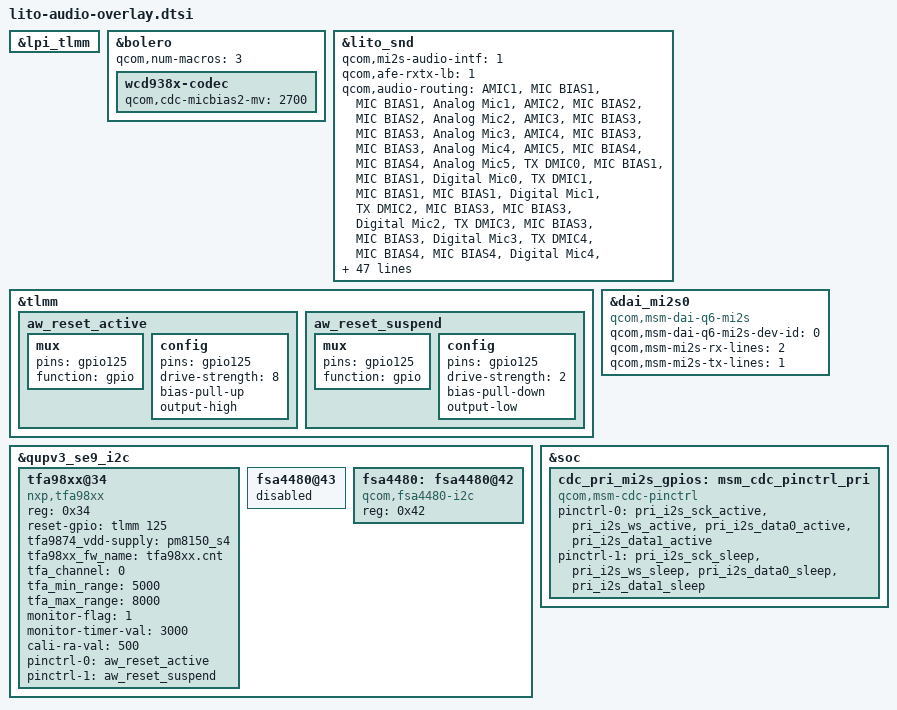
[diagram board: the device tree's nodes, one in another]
#define OPLUS_EXTERNAL_SPEAKER
#include "../../qcom/lito-audio-overlay.dtsi"
#undef OPLUS_EXTERNAL_SPEAKER

/delete-node/ &wsa_macro;
/delete-node/ &wsa_swr_gpios;
/delete-node/ &wsa_spkr_en1;
/delete-node/ &wsa_spkr_en2;
#include "oplus-audio-extend.dtsi"

&lpi_tlmm {
	/delete-node/ wsa_swr_clk_pin;
	/delete-node/ wsa_swr_data_pin;
};

&bolero {
	qcom,num-macros = <3>;
	wcd938x-codec {
		qcom,cdc-micbias2-mv = <2700>;
	};
};

&lito_snd {
	qcom,mi2s-audio-intf = <1>;
	qcom,afe-rxtx-lb = <1>;
	qcom,audio-routing =
		"AMIC1", "MIC BIAS1",
		"MIC BIAS1", "Analog Mic1",
		"AMIC2", "MIC BIAS2",
		"MIC BIAS2", "Analog Mic2",
		"AMIC3", "MIC BIAS3",
		"MIC BIAS3", "Analog Mic3",
		"AMIC4", "MIC BIAS3",
		"MIC BIAS3", "Analog Mic4",
		"AMIC5", "MIC BIAS4",
		"MIC BIAS4", "Analog Mic5",
		"TX DMIC0", "MIC BIAS1",
		"MIC BIAS1", "Digital Mic0",
		"TX DMIC1", "MIC BIAS1",
		"MIC BIAS1", "Digital Mic1",
		"TX DMIC2", "MIC BIAS3",
		"MIC BIAS3", "Digital Mic2",
		"TX DMIC3", "MIC BIAS3",
		"MIC BIAS3", "Digital Mic3",
		"TX DMIC4", "MIC BIAS4",
		"MIC BIAS4", "Digital Mic4",
		"TX DMIC5", "MIC BIAS4",
		"MIC BIAS4", "Digital Mic5",
		"IN1_HPHL", "HPHL_OUT",
		"IN2_HPHR", "HPHR_OUT",
		"IN3_AUX", "AUX_OUT",
		"TX SWR_ADC0", "ADC1_OUTPUT",
		"TX SWR_ADC1", "ADC2_OUTPUT",
		"TX SWR_ADC2", "ADC3_OUTPUT",
		"TX SWR_ADC3", "ADC4_OUTPUT",
		"TX SWR_DMIC0", "DMIC1_OUTPUT",
		"TX SWR_DMIC1", "DMIC2_OUTPUT",
		"TX SWR_DMIC2", "DMIC3_OUTPUT",
		"TX SWR_DMIC3", "DMIC4_OUTPUT",
		"TX SWR_DMIC4", "DMIC5_OUTPUT",
		"TX SWR_DMIC5", "DMIC6_OUTPUT",
		"TX SWR_DMIC6", "DMIC7_OUTPUT",
		"TX SWR_DMIC7", "DMIC8_OUTPUT",
		"RX_TX DEC0_INP", "TX DEC0 MUX",
		"RX_TX DEC1_INP", "TX DEC1 MUX",
		"RX_TX DEC2_INP", "TX DEC2 MUX",
		"RX_TX DEC3_INP", "TX DEC3 MUX",
		"VA_AIF1 CAP", "VA_SWR_CLK",
		"VA_AIF2 CAP", "VA_SWR_CLK",
		"VA_AIF3 CAP", "VA_SWR_CLK",
		"VA MIC BIAS1", "Digital Mic0",
		"VA MIC BIAS1", "Digital Mic1",
		"VA MIC BIAS3", "Digital Mic2",
		"VA MIC BIAS3", "Digital Mic3",
		"VA MIC BIAS4", "Digital Mic4",
		"VA MIC BIAS4", "Digital Mic5",
		"VA DMIC0", "VA MIC BIAS1",
		"VA DMIC1", "VA MIC BIAS1",
		"VA DMIC2", "VA MIC BIAS3",
		"VA DMIC3", "VA MIC BIAS3",
		"VA DMIC4", "VA MIC BIAS4",
		"VA DMIC5", "VA MIC BIAS4",
		"VA SWR_ADC0", "VA_SWR_CLK",
		"VA SWR_ADC1", "VA_SWR_CLK",
		"VA SWR_ADC2", "VA_SWR_CLK",
		"VA SWR_ADC3", "VA_SWR_CLK",
		"VA SWR_MIC0", "VA_SWR_CLK",
		"VA SWR_MIC1", "VA_SWR_CLK",
		"VA SWR_MIC2", "VA_SWR_CLK",
		"VA SWR_MIC3", "VA_SWR_CLK",
		"VA SWR_MIC4", "VA_SWR_CLK",
		"VA SWR_MIC5", "VA_SWR_CLK",
		"VA SWR_MIC6", "VA_SWR_CLK",
		"VA SWR_MIC7", "VA_SWR_CLK",
		"VA SWR_ADC0", "ADC1_OUTPUT",
		"VA SWR_ADC1", "ADC2_OUTPUT",
		"VA SWR_ADC2", "ADC3_OUTPUT",
		"VA SWR_ADC3", "ADC4_OUTPUT",
		"VA SWR_MIC0", "DMIC1_OUTPUT",
		"VA SWR_MIC1", "DMIC2_OUTPUT",
		"VA SWR_MIC2", "DMIC3_OUTPUT",
		"VA SWR_MIC3", "DMIC4_OUTPUT",
		"VA SWR_MIC4", "DMIC5_OUTPUT",
		"VA SWR_MIC5", "DMIC6_OUTPUT",
		"VA SWR_MIC6", "DMIC7_OUTPUT",
		"VA SWR_MIC7", "DMIC8_OUTPUT";
	qcom,msm-mbhc-hphl-swh = <0>;
	qcom,pri-mi2s-gpios = <&cdc_pri_mi2s_gpios>;
	qcom,wsa-max-devs = <0>;
	qcom,msm-mbhc-usbc-audio-supported = <1>;
	qcom,msm-mbhc-use-usbc-detect = <1>;
	qcom,msm-mbhc-hs-mic-max-threshold-mv = <2550>;
	fsa4480-i2c-handle = <&fsa4480>;
};

&tlmm {
	aw_reset_active: aw_reset_active {
		mux {
			pins = "gpio125";
			function = "gpio";
		};

		config {
			pins = "gpio125";
			drive-strength = <8>;
			bias-pull-up;
			output-high;
		};
	};

	aw_reset_suspend: aw_reset_suspend {
		mux {
			pins = "gpio125";
			function = "gpio";
		};

		config {
			pins = "gpio125";
			drive-strength = <2>;
			bias-pull-down;
			output-low;
		};
	};
};

&qupv3_se9_i2c {
	status = "okay";
	tfa98xx@34 {
		compatible = "nxp,tfa98xx";
		reg = <0x34>;
		reset-gpio = <&tlmm 125 0>;
		tfa9874_vdd-supply = <&pm8150_s4>;
		tfa98xx_fw_name = "tfa98xx.cnt";
		tfa_channel = <0>;
		tfa_min_range = <5000>;
		tfa_max_range = <8000>;
		monitor-flag = <1>;
		monitor-timer-val = <3000>;
		cali-ra-val = <500>;
		pinctrl-names = "aw_pinctrl_active","aw_pinctrl_suspend";
		pinctrl-0 = <&aw_reset_active>;
		pinctrl-1 = <&aw_reset_suspend>;
		status = "okay";
	};

	fsa4480@43 {
		status = "disabled";
	};

	fsa4480: fsa4480@42 {
		compatible = "qcom,fsa4480-i2c";
		reg = <0x42>;
	};
};

&dai_mi2s0 {
	compatible = "qcom,msm-dai-q6-mi2s";
	qcom,msm-dai-q6-mi2s-dev-id = <0>;
	qcom,msm-mi2s-rx-lines = <2>;
	qcom,msm-mi2s-tx-lines = <1>;
};

&soc {
	cdc_pri_mi2s_gpios: msm_cdc_pinctrl_pri {
		compatible = "qcom,msm-cdc-pinctrl";
		pinctrl-names = "aud_active", "aud_sleep";
		pinctrl-0 = <&pri_i2s_sck_active &pri_i2s_ws_active
			&pri_i2s_data0_active &pri_i2s_data1_active>;
		pinctrl-1 = <&pri_i2s_sck_sleep &pri_i2s_ws_sleep
			&pri_i2s_data0_sleep &pri_i2s_data1_sleep>;
	};
};
